# AST1060 register map
File version: 1.0
CPU: CM4 r0p1, little endian, MPU, FPU, 4 interrupt priority bits, 256 interrupts
Registers are 32-bit, read-write, reset 0x0 unless marked. A register's access mark holds for its fields unless they carry their own. Offsets are from the block's base; [hi:lo] are bit positions; {n}, {i} and the like mark numbered series.

## uart
Base 0x7E784000
0x00 UARTRBR — Receiving Buffer Register (DLAB = 0)
  [7:0] UARTRBR ro — Receiving Buffer Register
  [7:0] UARTTHR — Transmit Holding Register
0x00 UARTTHR — Transmit Holding Register (DLAB = 0)
  [7:0] UARTRBR1 ro — Receiving Buffer Register
  [7:0] UARTTHR1 — Transmit Holding Register
0x00 UARTDLL — Divisor Latch Low Register : (DLAB = 1)
  [7:0] TheLSBOfTheBdDivisorLatch — The LSB of the baud-rate divisor latch.
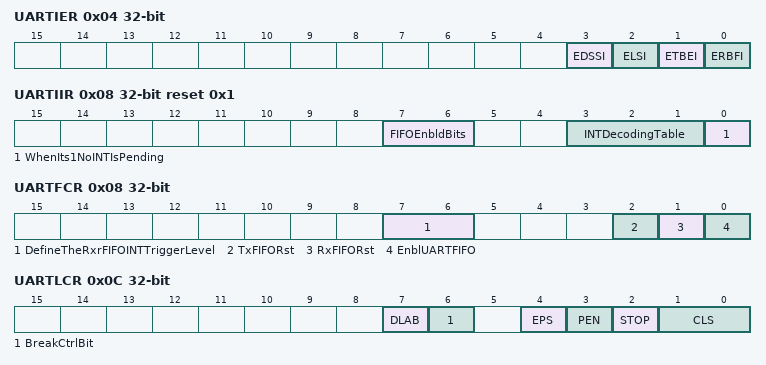
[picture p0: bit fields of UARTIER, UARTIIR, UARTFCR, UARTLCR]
0x04 UARTIER — Interrupt Enable Register (DLAB = 0)
  [3] EDSSI — Enable Modem Status Interrupt
  [2] ELSI — Enable Receiver Line Status Interrupt
  [1] ETBEI — Enable Transmitter Holding Register Empty Interrupt
  [0] ERBFI — Enable Received Data Available Interrupt
0x04 UARTDLH — Divisor Latch High Register : (DLAB = 1)
  [7:0] TheMSBOfTheBdDivisorLatch — The MSB of the baud-rate divisor latch.
0x08 UARTIIR reset 0x1 — Interrupt Identity Register
  [7:6] FIFOEnbldBits ro — FIFO-Enabled Bits
  [3:1] INTDecodingTable ro — Interrupt Decoding Table
  [0] WhenIts1NoINTIsPending ro — When it's "1", no interrupt is pending.
0x08 UARTFCR — FIFO Control Register
  [7:6] DefineTheRxrFIFOINTTriggerLevel — Define the Receiver FIFO Interrupt trigger level.
  [2] TxFIFORst — Transmit FIFO Reset
  [1] RxFIFORst — Receive FIFO Reset
  [0] EnblUARTFIFO — Enable UART FIFO
0x0C UARTLCR — Line Control Register
  [7] DLAB — Divisor latch access bit
  [6] BreakCtrlBit — Break Control bit.
  [4] EPS — Parity mode selection
  [3] PEN — Enable parity bit
  [2] STOP — Number of stop bits transmitted
  [1:0] CLS — Select number of bits per character
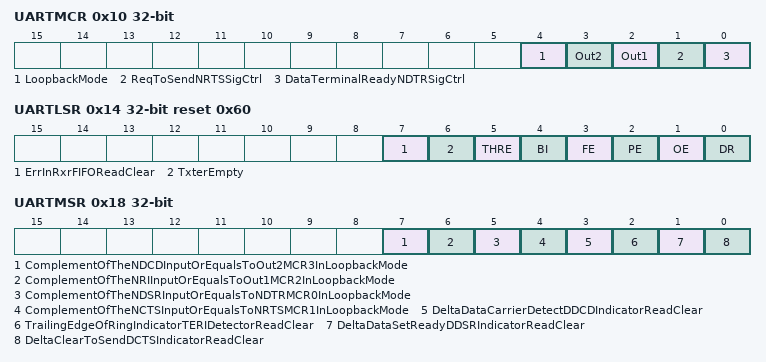
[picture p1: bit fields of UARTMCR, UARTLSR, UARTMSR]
0x10 UARTMCR — Modem Control Register
  [4] LoopbackMode
  [3] Out2
  [2] Out1
  [1] ReqToSendNRTSSigCtrl — Request To Send (nRTS) signal control.
  [0] DataTerminalReadyNDTRSigCtrl — Data Terminal Ready (nDTR) signal control.
0x14 UARTLSR reset 0x60 — Line Status Register
  [7] ErrInRxrFIFOReadClear ro — Error in Receiver FIFO (Read clear)
  [6] TxterEmpty ro — Transmitter empty
  [5] THRE ro — Transmitter holding register empty
  [4] BI ro — Break interrupt (Read clear)
  [3] FE ro — Framing error (Read clear)
  [2] PE ro — Parity error (Read clear)
  [1] OE ro — Overrun error (Read clear)
  [0] DR ro — Data ready
0x18 UARTMSR — Modem Status Register
  [7] ComplementOfTheNDCDInputOrEqualsToOut2MCR3InLoopbackMode ro, [6] ComplementOfTheNRIInputOrEqualsToOut1MCR2InLoopbackMode ro, [5] ComplementOfTheNDSRInputOrEqualsToNDTRMCR0InLoopbackMode ro, [4] ComplementOfTheNCTSInputOrEqualsToNRTSMCR1InLoopbackMode ro, [3] DeltaDataCarrierDetectDDCDIndicatorReadClear ro, [2] TrailingEdgeOfRingIndicatorTERIDetectorReadClear ro, [1] DeltaDataSetReadyDDSRIndicatorReadClear ro, [0] DeltaClearToSendDCTSIndicatorReadClear ro
0x1C UARTSCR — Scratch Register
  [7:0] ScratchBits

## i2cglobal
Base 0x7E7B0000
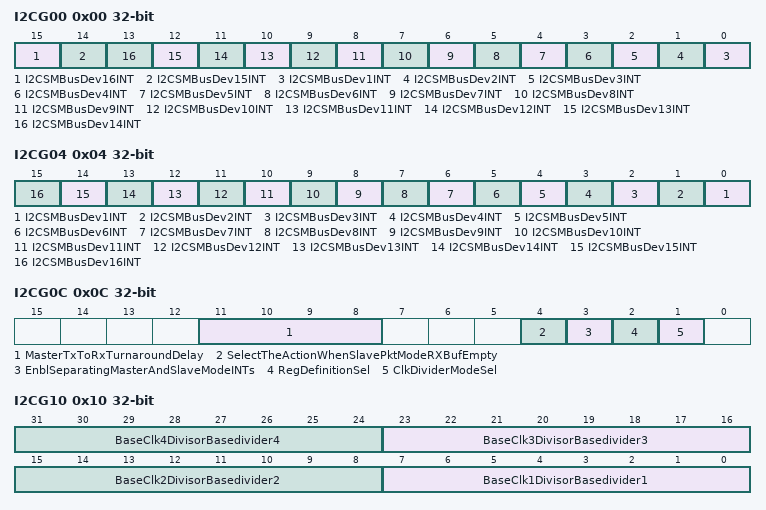
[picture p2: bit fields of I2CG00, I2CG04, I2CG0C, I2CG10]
0x00 I2CG00 — Device Master Mode Interrupt Status Register (I2CG0C[3] = 1)
  [15] I2CSMBusDev16INT ro — newverI2C/SMBus Device #16 Interrupt
  [14] I2CSMBusDev15INT ro — newverI2C/SMBus Device #15 Interrupt
  [n-1] I2CSMBusDev{n}INT ro (n=1..14) — I2C/SMBus Device #{n} Interrupt
0x04 I2CG04 — Device Slave Mode Interrupt Status Register
  [n-1] I2CSMBusDev{n}INT ro (n=1..16) — I2C/SMBus Device #{n} Interrupt
0x0C I2CG0C — Global Control Register
  [11:8] MasterTxToRxTurnaroundDelay — newverMaster transmit to receive turn-around delay
  [4] SelectTheActionWhenSlavePktModeRXBufEmpty — newverSelect the action when Slave packet mode RX buffer empty
  [3] EnblSeparatingMasterAndSlaveModeINTs — newverEnable separating master and slave mode interrupts
  [2] RegDefinitionSel — newverRegister definition selection
  [1] ClkDividerModeSel — newverClock divider mode selection
0x10 I2CG10 — New Clock Divider Control Register (I2CG0C[1] = 1)
  [8n-1:8n-8] BaseClk{n}DivisorBasedivider{n} (n=1..4) — Base clock {n} divisor, base_divider_{n}
